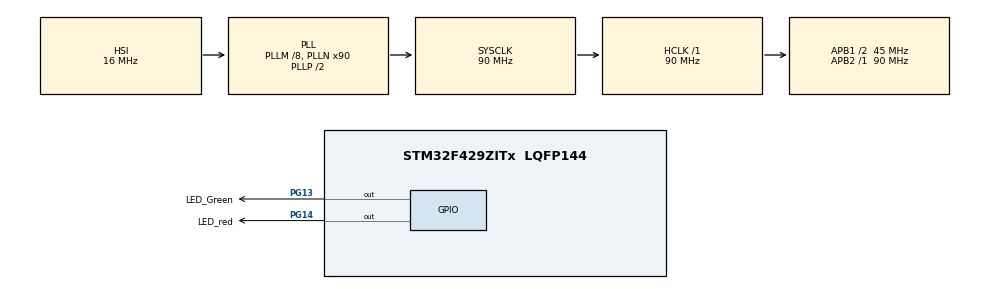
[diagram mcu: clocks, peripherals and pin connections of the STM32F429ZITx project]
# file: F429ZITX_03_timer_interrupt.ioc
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Mcu.Family=STM32F4
Mcu.Name=STM32F429ZITx
Mcu.Package=LQFP144
NVIC.PriorityGroup=NVIC_PRIORITYGROUP_4
NVIC.TIM1_TRG_COM_TIM11_IRQn=true\:0\:0\:false\:false\:true\:true
NVIC.TIM1_UP_TIM10_IRQn=true\:0\:0\:false\:false\:true\:true
PG13.GPIO_Label=LED_Green
PG13.Signal=GPIO_Output
PG14.GPIO_Label=LED_red
PG14.Signal=GPIO_Output
PH0/OSC_IN.Mode=HSE-External-Oscillator
PH0/OSC_IN.Signal=RCC_OSC_IN
PH1/OSC_OUT.Mode=HSE-External-Oscillator
PH1/OSC_OUT.Signal=RCC_OSC_OUT
ProjectManager.HeapSize=0x200
ProjectManager.StackSize=0x400
ProjectManager.TargetToolchain=TrueSTUDIO
RCC.48MHZClocksFreq_Value=45000000
RCC.AHBFreq_Value=90000000
RCC.APB1CLKDivider=RCC_HCLK_DIV2
RCC.APB1Freq_Value=45000000
RCC.APB1TimFreq_Value=90000000
RCC.APB2Freq_Value=90000000
RCC.APB2TimFreq_Value=90000000
RCC.CortexFreq_Value=90000000
RCC.HCLKFreq_Value=90000000
RCC.HSE_VALUE=8000000
RCC.HSI_VALUE=16000000
RCC.LSE_VALUE=32768
RCC.PLLM=8
RCC.PLLN=90
RCC.SYSCLKFreq_VALUE=90000000
RCC.SYSCLKSource=RCC_SYSCLKSOURCE_PLLCLK
RCC.VCOOutputFreq_Value=180000000
TIM10.Period=8999
TIM10.Prescaler=9999
TIM11.Period=2249
TIM11.Prescaler=9999
VP_TIM10_VS_ClockSourceINT.Mode=Enable_Timer
VP_TIM11_VS_ClockSourceINT.Mode=Enable_Timer
board=F429ZITX_03_timer_interrupt

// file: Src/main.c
/**
  ******************************************************************************
  * @file           : main.c
  * @brief          : Main program body
  ******************************************************************************
  ** This notice applies to any and all portions of this file
  * that are not between comment pairs USER CODE BEGIN and
  * USER CODE END. Other portions of this file, whether
  * inserted by the user or by software development tools
  * are owned by their respective copyright owners.
  *
  * COPYRIGHT(c) 2018 STMicroelectronics
  *
  * Redistribution and use in source and binary forms, with or without modification,
  * are permitted provided that the following conditions are met:
  *   1. Redistributions of source code must retain the above copyright notice,
  *      this list of conditions and the following disclaimer.
  *   2. Redistributions in binary form must reproduce the above copyright notice,
  *      this list of conditions and the following disclaimer in the documentation
  *      and/or other materials provided with the distribution.
  *   3. Neither the name of STMicroelectronics nor the names of its contributors
  *      may be used to endorse or promote products derived from this software
  *      without specific prior written permission.
  *
  * THIS SOFTWARE IS PROVIDED BY THE COPYRIGHT HOLDERS AND CONTRIBUTORS "AS IS"
  * AND ANY EXPRESS OR IMPLIED WARRANTIES, INCLUDING, BUT NOT LIMITED TO, THE
  * IMPLIED WARRANTIES OF MERCHANTABILITY AND FITNESS FOR A PARTICULAR PURPOSE ARE
  * DISCLAIMED. IN NO EVENT SHALL THE COPYRIGHT HOLDER OR CONTRIBUTORS BE LIABLE
  * FOR ANY DIRECT, INDIRECT, INCIDENTAL, SPECIAL, EXEMPLARY, OR CONSEQUENTIAL
  * DAMAGES (INCLUDING, BUT NOT LIMITED TO, PROCUREMENT OF SUBSTITUTE GOODS OR
  * SERVICES; LOSS OF USE, DATA, OR PROFITS; OR BUSINESS INTERRUPTION) HOWEVER
  * CAUSED AND ON ANY THEORY OF LIABILITY, WHETHER IN CONTRACT, STRICT LIABILITY,
  * OR TORT (INCLUDING NEGLIGENCE OR OTHERWISE) ARISING IN ANY WAY OUT OF THE USE
  * OF THIS SOFTWARE, EVEN IF ADVISED OF THE POSSIBILITY OF SUCH DAMAGE.
  *
  ******************************************************************************
  */
#include "main.h"
#include "stm32f4xx_hal.h"

TIM_HandleTypeDef htim10;
TIM_HandleTypeDef htim11;

/* USER CODE BEGIN PV */
/* Private variables ---------------------------------------------------------*/

/* USER CODE END PV */

void SystemClock_Config(void);
static void MX_GPIO_Init(void);
static void MX_TIM10_Init(void);
static void MX_TIM11_Init(void);

/* USER CODE BEGIN PFP */
/* Private function prototypes -----------------------------------------------*/
void HAL_TIM_PeriodElapsedCallback(TIM_HandleTypeDef *htim){

	volatile static uint16_t counter = 0;//licznik
	volatile static uint16_t counter2 = 0;

	++counter; // inkremencjata licznika zczestotliwoscia 2Hz
	++counter2;

	if(counter == 3) {
		counter = 0; //wyzeruj conter
		if(htim->Instance == TIM10){ // je¿eli przerwaniee pochodzi od timera 10
			HAL_GPIO_TogglePin(LED_Green_GPIO_Port,LED_Green_Pin);

		}
	}
	if(counter2 == 5){
		counter2 = 0;
		if(htim->Instance == TIM11){// je¿eli przerwaniee pochodzi od timera 10
			HAL_GPIO_TogglePin(LED_red_GPIO_Port,LED_red_Pin);
		}
	}

}
/* USER CODE END PFP */

int main(void)
{

  /* MCU Configuration----------------------------------------------------------*/

  /* Reset of all peripherals, Initializes the Flash interface and the Systick. */
  HAL_Init();

  /* Configure the system clock */
  SystemClock_Config();

  /* Initialize all configured peripherals */
  MX_GPIO_Init();
  MX_TIM10_Init();
  MX_TIM11_Init();
  /* USER CODE BEGIN 2 */
  HAL_TIM_Base_Start_IT(&htim10);
  HAL_TIM_Base_Start_IT(&htim11);
  /* USER CODE END 2 */

  /* Infinite loop */
  while (1)
  {

  }

}

void SystemClock_Config(void)
{

  RCC_OscInitTypeDef RCC_OscInitStruct;
  RCC_ClkInitTypeDef RCC_ClkInitStruct;

    /**Configure the main internal regulator output voltage
    */
  __HAL_RCC_PWR_CLK_ENABLE();

  __HAL_PWR_VOLTAGESCALING_CONFIG(PWR_REGULATOR_VOLTAGE_SCALE3);

    /**Initializes the CPU, AHB and APB busses clocks
    */
  RCC_OscInitStruct.OscillatorType = RCC_OSCILLATORTYPE_HSI;
  RCC_OscInitStruct.HSIState = RCC_HSI_ON;
  RCC_OscInitStruct.HSICalibrationValue = 16;
  RCC_OscInitStruct.PLL.PLLState = RCC_PLL_ON;
  RCC_OscInitStruct.PLL.PLLSource = RCC_PLLSOURCE_HSI;
  RCC_OscInitStruct.PLL.PLLM = 8;
  RCC_OscInitStruct.PLL.PLLN = 90;
  RCC_OscInitStruct.PLL.PLLP = RCC_PLLP_DIV2;
  RCC_OscInitStruct.PLL.PLLQ = 4;
  if (HAL_RCC_OscConfig(&RCC_OscInitStruct) != HAL_OK)
  {
    _Error_Handler(__FILE__, __LINE__);
  }

    /**Activate the Over-Drive mode
    */
  if (HAL_PWREx_EnableOverDrive() != HAL_OK)
  {
    _Error_Handler(__FILE__, __LINE__);
  }

    /**Initializes the CPU, AHB and APB busses clocks
    */
  RCC_ClkInitStruct.ClockType = RCC_CLOCKTYPE_HCLK|RCC_CLOCKTYPE_SYSCLK
                              |RCC_CLOCKTYPE_PCLK1|RCC_CLOCKTYPE_PCLK2;
  RCC_ClkInitStruct.SYSCLKSource = RCC_SYSCLKSOURCE_PLLCLK;
  RCC_ClkInitStruct.AHBCLKDivider = RCC_SYSCLK_DIV1;
  RCC_ClkInitStruct.APB1CLKDivider = RCC_HCLK_DIV2;
  RCC_ClkInitStruct.APB2CLKDivider = RCC_HCLK_DIV1;

  if (HAL_RCC_ClockConfig(&RCC_ClkInitStruct, FLASH_LATENCY_2) != HAL_OK)
  {
    _Error_Handler(__FILE__, __LINE__);
  }

    /**Configure the Systick interrupt time
    */
  HAL_SYSTICK_Config(HAL_RCC_GetHCLKFreq()/1000);

    /**Configure the Systick
    */
  HAL_SYSTICK_CLKSourceConfig(SYSTICK_CLKSOURCE_HCLK);

  /* SysTick_IRQn interrupt configuration */
  HAL_NVIC_SetPriority(SysTick_IRQn, 0, 0);
}

/* TIM10 init function */
static void MX_TIM10_Init(void)
{

  htim10.Instance = TIM10;
  htim10.Init.Prescaler = 9999;
  htim10.Init.CounterMode = TIM_COUNTERMODE_UP;
  htim10.Init.Period = 8999;
  htim10.Init.ClockDivision = TIM_CLOCKDIVISION_DIV1;
  if (HAL_TIM_Base_Init(&htim10) != HAL_OK)
  {
    _Error_Handler(__FILE__, __LINE__);
  }

}

/* TIM11 init function */
static void MX_TIM11_Init(void)
{

  htim11.Instance = TIM11;
  htim11.Init.Prescaler = 9999;
  htim11.Init.CounterMode = TIM_COUNTERMODE_UP;
  htim11.Init.Period = 2249;
  htim11.Init.ClockDivision = TIM_CLOCKDIVISION_DIV1;
  if (HAL_TIM_Base_Init(&htim11) != HAL_OK)
  {
    _Error_Handler(__FILE__, __LINE__);
  }

}

/** Configure pins as
        * Analog
        * Input
        * Output
        * EVENT_OUT
        * EXTI
*/
static void MX_GPIO_Init(void)
{

  GPIO_InitTypeDef GPIO_InitStruct;

  /* GPIO Ports Clock Enable */
  __HAL_RCC_GPIOH_CLK_ENABLE();
  __HAL_RCC_GPIOG_CLK_ENABLE();

  /*Configure GPIO pin Output Level */
  HAL_GPIO_WritePin(GPIOG, LED_Green_Pin|LED_red_Pin, GPIO_PIN_RESET);

  /*Configure GPIO pins : LED_Green_Pin LED_red_Pin */
  GPIO_InitStruct.Pin = LED_Green_Pin|LED_red_Pin;
  GPIO_InitStruct.Mode = GPIO_MODE_OUTPUT_PP;
  GPIO_InitStruct.Pull = GPIO_NOPULL;
  GPIO_InitStruct.Speed = GPIO_SPEED_FREQ_LOW;
  HAL_GPIO_Init(GPIOG, &GPIO_InitStruct);

}

void _Error_Handler(char *file, int line)
{
  while(1)
  {
  }
}

/************************ (C) COPYRIGHT STMicroelectronics *****END OF FILE****/
